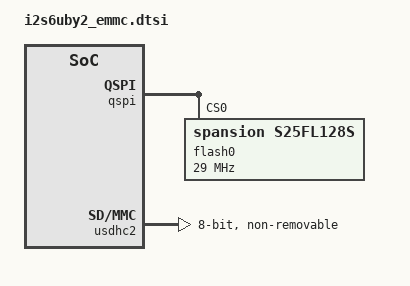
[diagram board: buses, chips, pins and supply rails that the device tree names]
&qspi {
	pinctrl-names = "default";
	pinctrl-0 = <&pinctrl_qspi>;
	ddrsmp=<0>;

	flash0: s25fl128s@0 {
		reg = <0>;
		#address-cells = <1>;
		#size-cells = <1>;
		compatible = "spansion,s25fl128s";
		spi-max-frequency = <29000000>;
	};
};

&usdhc2 {
	pinctrl-names = "default";
	pinctrl-0 = <&pinctrl_usdhc2_8bit>;
	bus-width = <8>;
	non-removable;
	no-1-8-v;
};
